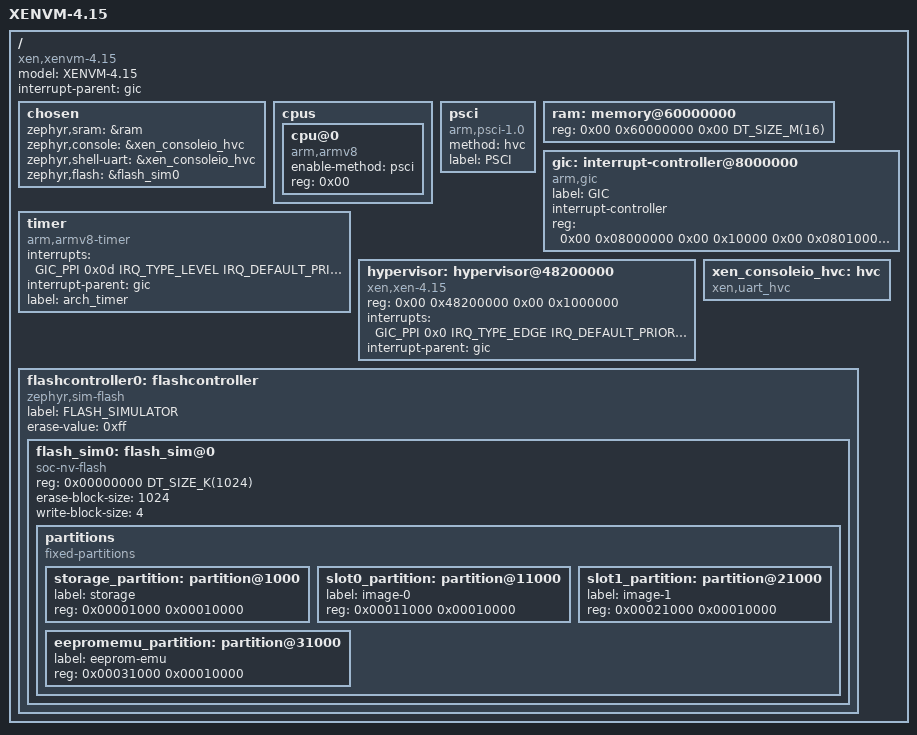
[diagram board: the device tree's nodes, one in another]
/*
 * Copyright (c) 2020 EPAM Systems
 *
 * SPDX-License-Identifier: Apache-2.0
 *
 * This file was created by running
 *
 * # LIBXL_DEBUG_DUMP_DTB=domu-libxl.dtb xl create zephyr.conf
 *
 * decompilling resulting domu-libxl.dtb and then manually aligning it
 * with zephyr requirements.
 */

/dts-v1/;

#include <mem.h>
#include <arm64/armv8-a.dtsi>
#include <dt-bindings/interrupt-controller/arm-gic.h>

/ {
	model = "XENVM-4.15";
	compatible = "xen,xenvm-4.15", "xen,xenvm";
	interrupt-parent = <&gic>;
	#address-cells = <0x02>;
	#size-cells = <0x02>;

	chosen {
		zephyr,sram = &ram;
		zephyr,console = &xen_consoleio_hvc;
		zephyr,shell-uart = &xen_consoleio_hvc;
		zephyr,flash = &flash_sim0;
	};

	cpus {
		#address-cells = <0x01>;
		#size-cells = <0x00>;

		cpu@0 {
			device_type = "cpu";
			compatible = "arm,armv8";
			enable-method = "psci";
			reg = <0x00>;
		};
	};

	psci {
		compatible = "arm,psci-1.0", "arm,psci-0.2", "arm,psci";
		method = "hvc";
		label = "PSCI";
	};

	ram: memory@60000000 {
		device_type = "mmio-sram";
		reg = <0x00 0x60000000 0x00 DT_SIZE_M(16)>;
	};

	gic: interrupt-controller@8000000 {
		compatible = "arm,gic";
		label = "GIC";
		#interrupt-cells = <0x04>;
		#address-cells = <0x00>;
		interrupt-controller;
		reg = <0x00 0x08000000 0x00 0x10000 0x00 0x08010000 0x00 0x40000>;
	};

	timer {
		compatible = "arm,armv8-timer";
		interrupts = <GIC_PPI 0x0d IRQ_TYPE_LEVEL IRQ_DEFAULT_PRIORITY
			      GIC_PPI 0x0e IRQ_TYPE_LEVEL IRQ_DEFAULT_PRIORITY
			      GIC_PPI 0x0b IRQ_TYPE_LEVEL IRQ_DEFAULT_PRIORITY>;
		interrupt-parent = <&gic>;
		label = "arch_timer";
	};

	hypervisor: hypervisor@48200000 {
		compatible = "xen,xen-4.15", "xen,xen";
		reg = <0x00 0x48200000 0x00 0x1000000>;
		interrupts = <GIC_PPI 0x0 IRQ_TYPE_EDGE IRQ_DEFAULT_PRIORITY>;
		interrupt-parent = <&gic>;
	};

	xen_consoleio_hvc: hvc {
		compatible = "xen,uart_hvc";
		status = "okay";
	};
	flashcontroller0: flashcontroller {
		compatible = "zephyr,sim-flash";
		label = "FLASH_SIMULATOR";
		#address-cells = <1>;
		#size-cells = <1>;
		erase-value = <0xff>;
		flash_sim0: flash_sim@0 {
			compatible = "soc-nv-flash";
			reg = <0x00000000 DT_SIZE_K(1024)>;
			erase-block-size = <1024>;
			write-block-size = <4>;
		};
	};
};

&flash_sim0 {
	partitions {
		compatible = "fixed-partitions";
		#address-cells = <1>;
		#size-cells = <1>;
/*
 * Storage partition will be used by FCB/LittleFS/NVS
 * if enabled.
 */
		storage_partition: partition@1000 {
			label = "storage";
			reg = <0x00001000 0x00010000>;
		};
		slot0_partition: partition@11000 {
			 label = "image-0";
			 reg = <0x00011000 0x00010000>;
		};
		slot1_partition: partition@21000 {
			 label = "image-1";
			 reg = <0x00021000 0x00010000>;
		};
		eepromemu_partition: partition@31000 {
			label = "eeprom-emu";
			reg = <0x00031000 0x00010000>;
		};
	};
};
